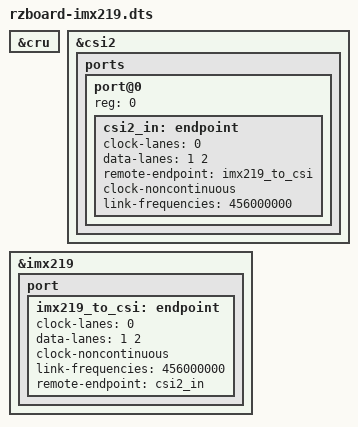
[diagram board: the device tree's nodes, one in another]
/*
 * Copyright 2022 AVNET
 *
 * This program is free software; you can redistribute it and/or
 * modify it under the terms of the GNU General Public License
 * as published by the Free Software Foundation; either version 2
 * of the License, or (at your option) any later version.
 *
 * This program is distributed in the hope that it will be useful,
 * but WITHOUT ANY WARRANTY; without even the implied warranty of
 * MERCHANTABILITY or FITNESS FOR A PARTICULAR PURPOSE. See the
 * GNU General Public License for more details.
 */

/dts-v1/;
/plugin/;

&cru {
	status = "okay";
};

&csi2 {
	status = "okay";
	ports {
		#address-cells = <1>;
		#size-cells = <0>;
		port@0 {
			reg = <0>;
			csi2_in: endpoint {
				clock-lanes = <0>;
				data-lanes = <1 2>;
				remote-endpoint = <&imx219_to_csi>;
				clock-noncontinuous;
				link-frequencies =
				/bits/ 64 <456000000>;
			};
		};
	};
};

&imx219 {
	status = "okay";
	port {
		imx219_to_csi: endpoint {
			clock-lanes = <0>;
			data-lanes = <1 2>;
			clock-noncontinuous;
			link-frequencies =
				/bits/ 64 <456000000>;
			remote-endpoint = <&csi2_in>;
		};
	};
};
